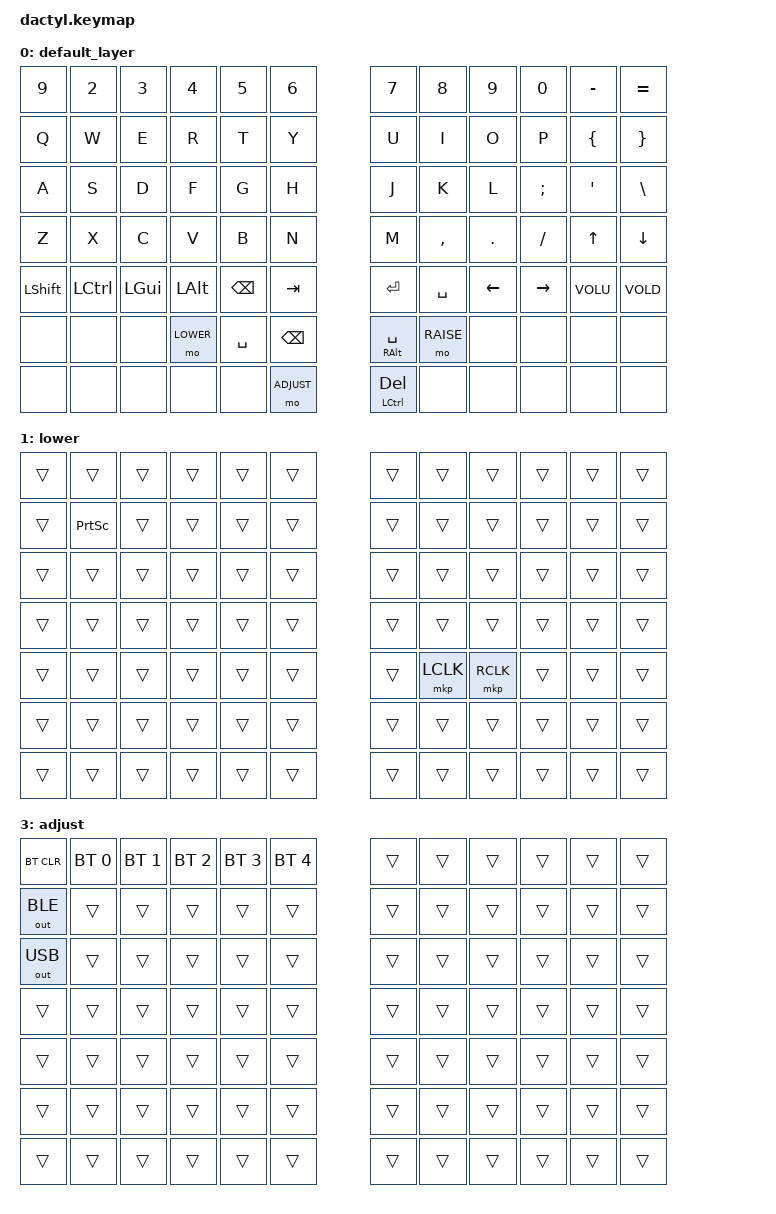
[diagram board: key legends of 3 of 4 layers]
#include <behaviors.dtsi>
#include <dt-bindings/zmk/keys.h>
#include <dt-bindings/zmk/bt.h>
#include <dt-bindings/zmk/outputs.h>
#include <dt-bindings/zmk/mouse.h>

#define DEFAULT 0
#define LOWER 1
#define RAISE 2
#define ADJUST 3

/ {
    keymap {
        compatible = "zmk,keymap";

        default_layer {
            bindings = <
/* left hand */                                                              /* right hand */
&kp N9     &kp N2     &kp N3     &kp N4     &kp N5     &kp N6                    &kp N7     &kp N8     &kp N9     &kp N0     &kp MINUS  &kp EQUAL
&kp Q      &kp W      &kp E      &kp R      &kp T      &kp Y                     &kp U      &kp I      &kp O      &kp P      &kp LBRC   &kp RBRC
&kp A      &kp S      &kp D      &kp F      &kp G      &kp H                     &kp J      &kp K      &kp L      &kp SEMI   &kp SQT    &kp BSLH
&kp Z      &kp X      &kp C      &kp V      &kp B      &kp N                     &kp M      &kp COMMA  &kp DOT    &kp FSLH   &kp UP     &kp DOWN
&kp LSHFT  &kp LCTRL  &kp LGUI   &kp LALT   &kp BSPC   &kp TAB                   &kp ENTER  &kp SPACE  &kp LEFT   &kp RIGHT  &kp VOLU   &kp VOLD
&none      &none      &none      &mo LOWER  &kp SPACE  &kp BSPC                  &mt RALT SPACE &mo RAISE  &none      &none      &none      &none
&none      &none      &none      &none      &none      &mo ADJUST                &mt LCTRL DEL &none      &none      &none      &none      &none
            >;
        };

        lower {
            bindings = <
/* left hand */                                                              /* right hand */
&trans     &trans     &trans     &trans     &trans     &trans                    &trans     &trans     &trans     &trans     &trans     &trans
&trans     &kp PSCRN  &trans     &trans     &trans     &trans                    &trans     &trans     &trans     &trans     &trans     &trans
&trans     &trans     &trans     &trans     &trans     &trans                    &trans     &trans     &trans     &trans     &trans     &trans
&trans     &trans     &trans     &trans     &trans     &trans                    &trans     &trans     &trans     &trans     &trans     &trans
&trans     &trans     &trans     &trans     &trans     &trans                    &trans     &mkp LCLK  &mkp RCLK  &trans     &trans     &trans
&trans     &trans     &trans     &trans     &trans     &trans                    &trans     &trans     &trans     &trans     &trans     &trans
&trans     &trans     &trans     &trans     &trans     &trans                    &trans     &trans     &trans     &trans     &trans     &trans
            >;
        };

        raise {
            bindings = <
/* left hand */                                                              /* right hand */
&kp F1     &kp F2     &kp F3     &kp F4     &kp F5     &kp F6                    &kp F7     &kp F8     &kp F9     &kp F10    &kp F11    &kp F12
&trans     &trans     &trans     &trans     &trans     &trans                    &trans     &trans     &trans     &trans     &trans     &trans
&kp EXCL   &kp AT     &kp HASH   &kp DLLR   &kp PRCNT  &kp CARET                 &kp AMPS   &kp ASTRK  &kp LPAR   &kp RPAR   &kp BSLH   &kp PIPE
&trans     &trans     &trans     &trans     &trans     &trans                    &trans     &trans     &trans     &trans     &trans     &trans
&trans     &trans     &trans     &trans     &trans     &trans                    &trans     &trans     &trans     &kp HOME   &kp PG_DN  &kp PG_UP  &kp END
&trans     &trans     &trans     &trans     &trans     &trans                    &trans     &trans     &trans     &trans     &trans     &trans
&trans     &trans     &trans     &trans     &trans     &trans                    &trans     &trans     &trans     &trans     &trans     &trans
            >;
        };

	    adjust {
            compatible = "zmk,keymap";
		    bindings = <
/* left hand */                                                              /* right hand */
&bt BT_CLR &bt BT_SEL 0 &bt BT_SEL 1 &bt BT_SEL 2 &bt BT_SEL 3 &bt BT_SEL 4      &trans     &trans     &trans     &trans     &trans     &trans
&out OUT_BLE &trans     &trans     &trans     &trans     &trans                    &trans     &trans     &trans     &trans     &trans     &trans
&out OUT_USB &trans     &trans     &trans     &trans     &trans                    &trans     &trans     &trans     &trans     &trans     &trans
&trans     &trans     &trans     &trans     &trans     &trans                    &trans     &trans     &trans     &trans     &trans     &trans
&trans     &trans     &trans     &trans     &trans     &trans                    &trans     &trans     &trans     &trans     &trans     &trans
&trans     &trans     &trans     &trans     &trans     &trans                    &trans     &trans     &trans     &trans     &trans     &trans
&trans     &trans     &trans     &trans     &trans     &trans                    &trans     &trans     &trans     &trans     &trans     &trans
            >;
        };
    };
};
